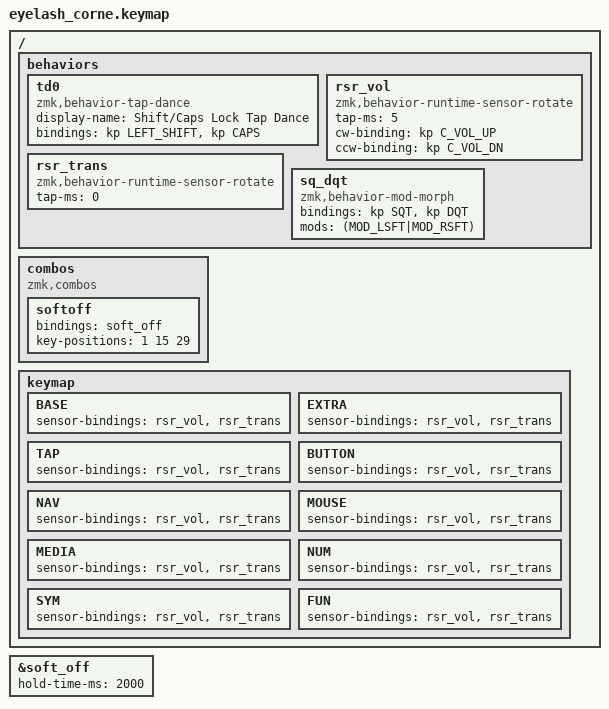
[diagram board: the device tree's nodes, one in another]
#define ZMK_POINTING_DEFAULT_MOVE_VAL 1200
#define ZMK_POINTING_DEFAULT_SCRL_VAL 25

#include <input/processors.dtsi>
#include <zephyr/dt-bindings/input/input-event-codes.h>
#include <behaviors.dtsi>
#include <behaviors/runtime-sensor-rotate.dtsi>
#include <dt-bindings/zmk/bt.h>
#include <dt-bindings/zmk/keys.h>
#include <dt-bindings/zmk/outputs.h>
#include <dt-bindings/zmk/pointing.h>
#include <dt-bindings/zmk/rgb.h>

&soft_off { hold-time-ms = <2000>; };

/ {
    behaviors {
        td0: td0 {
            compatible = "zmk,behavior-tap-dance";
            #binding-cells = <0>;
            display-name = "Shift/Caps Lock Tap Dance";
            bindings = <&kp LEFT_SHIFT>, <&kp CAPS>;
        };

        rsr_vol: rsr_vol {
            compatible = "zmk,behavior-runtime-sensor-rotate";
            #sensor-binding-cells = <0>;
            tap-ms = <5>;
            cw-binding = <&kp C_VOL_UP>;
            ccw-binding = <&kp C_VOL_DN>;
        };

        rsr_trans: rsr_trans {
            compatible = "zmk,behavior-runtime-sensor-rotate";
            #sensor-binding-cells = <0>;
            tap-ms = <0>;
        };

        sq_dqt: sq_dqt {
            compatible = "zmk,behavior-mod-morph";
            #binding-cells = <0>;
            bindings = <&kp SQT>, <&kp DQT>;
            mods = <(MOD_LSFT|MOD_RSFT)>;
        };
    };

    combos {
        compatible = "zmk,combos";

        softoff {
            bindings = <&soft_off>;
            key-positions = <1 15 29>;
        };
    };
};

#include "miryoku/custom_config.h"
#include "miryoku/mapping/48/eyelash_corne.h"
#include "miryoku/miryoku.dtsi"

/ {
    keymap {
        BASE { sensor-bindings = <&rsr_vol &rsr_trans>; };
        EXTRA { sensor-bindings = <&rsr_vol &rsr_trans>; };
        TAP { sensor-bindings = <&rsr_vol &rsr_trans>; };
        BUTTON { sensor-bindings = <&rsr_vol &rsr_trans>; };
        NAV { sensor-bindings = <&rsr_vol &rsr_trans>; };
        MOUSE { sensor-bindings = <&rsr_vol &rsr_trans>; };
        MEDIA { sensor-bindings = <&rsr_vol &rsr_trans>; };
        NUM { sensor-bindings = <&rsr_vol &rsr_trans>; };
        SYM { sensor-bindings = <&rsr_vol &rsr_trans>; };
        FUN { sensor-bindings = <&rsr_vol &rsr_trans>; };
    };
};
